# STM32WL54CCU6@M0 register map
File version: 1.0
Registers are 32-bit, access not given, reset 0x0 unless marked. A register's access mark holds for its fields unless they carry their own. Offsets are from the block's base; [hi:lo] are bit positions; {n}, {i} and the like mark numbered series.

## TAMP
Base 0x4000B000
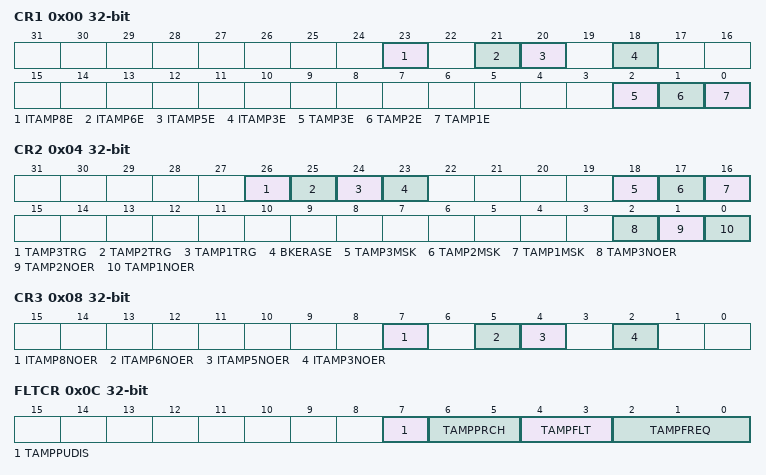
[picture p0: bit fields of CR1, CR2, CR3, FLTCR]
0x00 CR1
  [23] ITAMP8E, [21] ITAMP6E, [20] ITAMP5E, [18] ITAMP3E, [2] TAMP3E, [1] TAMP2E, [0] TAMP1E
0x04 CR2
  [26] TAMP3TRG, [25] TAMP2TRG, [24] TAMP1TRG, [23] BKERASE, [18] TAMP3MSK, [17] TAMP2MSK, [16] TAMP1MSK, [2] TAMP3NOER, [1] TAMP2NOER, [0] TAMP1NOER
0x08 CR3
  [7] ITAMP8NOER, [5] ITAMP6NOER, [4] ITAMP5NOER, [2] ITAMP3NOER
0x0C FLTCR
  [7] TAMPPUDIS, [6:5] TAMPPRCH, [4:3] TAMPFLT, [2:0] TAMPFREQ
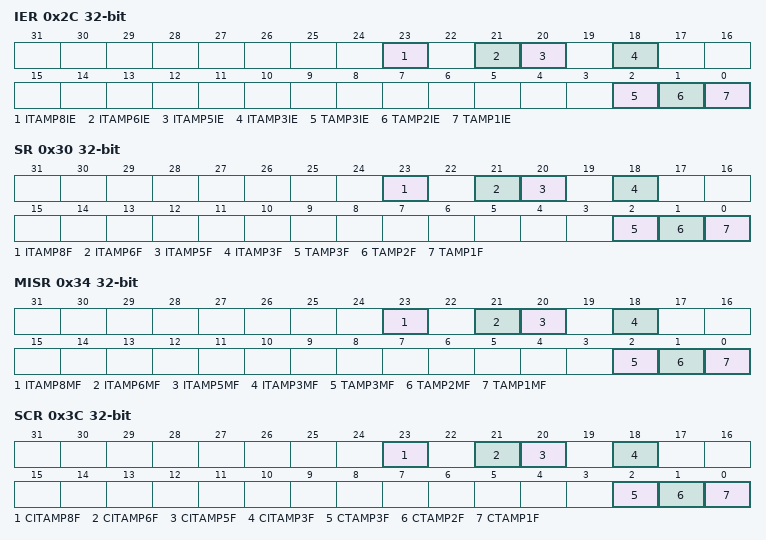
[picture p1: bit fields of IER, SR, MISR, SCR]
0x2C IER
  [23] ITAMP8IE, [21] ITAMP6IE, [20] ITAMP5IE, [18] ITAMP3IE, [2] TAMP3IE, [1] TAMP2IE, [0] TAMP1IE
0x30 SR
  [23] ITAMP8F, [21] ITAMP6F, [20] ITAMP5F, [18] ITAMP3F, [2] TAMP3F, [1] TAMP2F, [0] TAMP1F
0x34 MISR
  [23] ITAMP8MF, [21] ITAMP6MF, [20] ITAMP5MF, [18] ITAMP3MF, [2] TAMP3MF, [1] TAMP2MF, [0] TAMP1MF
0x3C SCR
  [23] CITAMP8F, [21] CITAMP6F, [20] CITAMP5F, [18] CITAMP3F, [2] CTAMP3F, [1] CTAMP2F, [0] CTAMP1F
0x40 COUNTR
  [31:0] COUNT
{0x100+4i} BKP{i}R (i=0..19)
  [31:0] BKP

## SYSCFG
Base 0x40010000
Same registers: SYSCFG 0x40010100, SYSCFG 0x40010100
0x00 MEMRMP
  [2:0] MEM_MODE
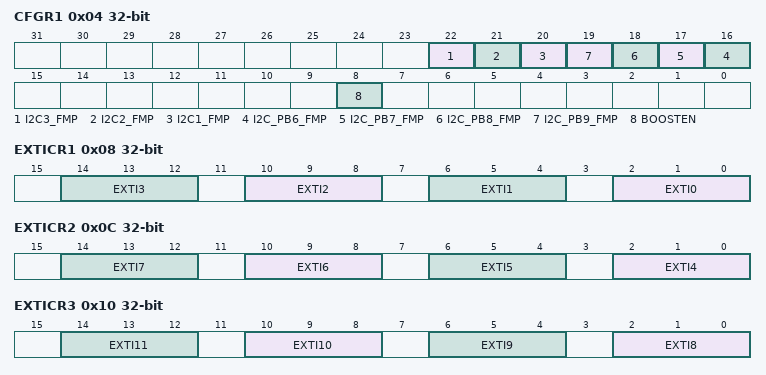
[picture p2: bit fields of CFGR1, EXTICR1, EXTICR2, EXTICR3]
0x04 CFGR1
  [22] I2C3_FMP, [21] I2C2_FMP, [20] I2C1_FMP, [n+10] I2C_PB{n}_FMP (n=6..9), [8] BOOSTEN
0x08 EXTICR1
  [4n+2:4n] EXTI{n} (n=0..3)
0x0C EXTICR2
  [4n-14:4n-16] EXTI{n} (n=4..7)
0x10 EXTICR3
  [4n-30:4n-32] EXTI{n} (n=8..11)
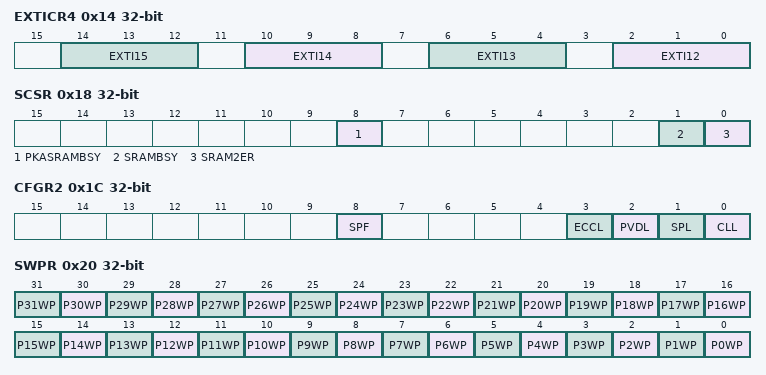
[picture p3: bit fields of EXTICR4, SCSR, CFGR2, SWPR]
0x14 EXTICR4
  [4n-46:4n-48] EXTI{n} (n=12..15)
0x18 SCSR
  [8] PKASRAMBSY, [1] SRAMBSY, [0] SRAM2ER
0x1C CFGR2
  [8] SPF, [3] ECCL, [2] PVDL, [1] SPL, [0] CLL
0x20 SWPR
  [n] P{n}WP (n=0..31)
0x24 SKR
  [7:0] KEY
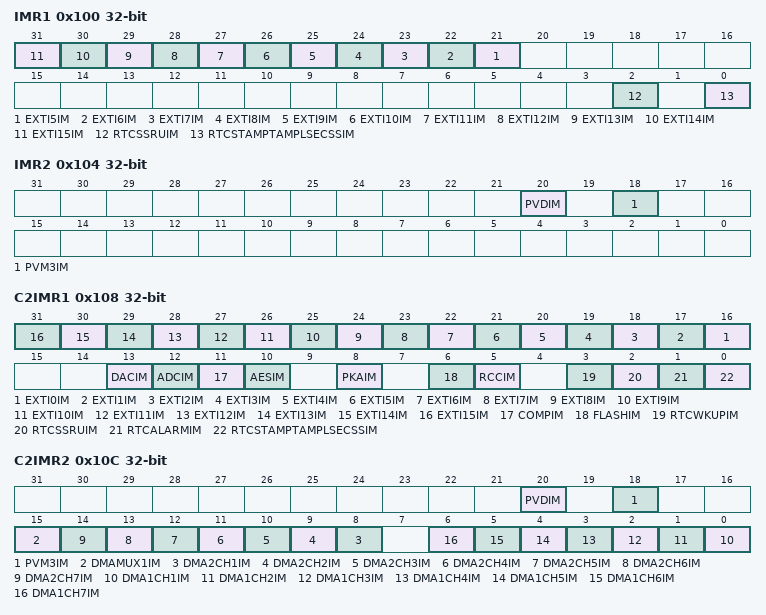
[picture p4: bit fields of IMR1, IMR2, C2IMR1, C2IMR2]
0x100 IMR1
  [n+16] EXTI{n}IM (n=5..15), [2] RTCSSRUIM, [0] RTCSTAMPTAMPLSECSSIM
0x104 IMR2
  [20] PVDIM, [18] PVM3IM
0x108 C2IMR1
  [n+16] EXTI{n}IM (n=0..15), [13] DACIM, [12] ADCIM, [11] COMPIM, [10] AESIM, [8] PKAIM, [6] FLASHIM, [5] RCCIM, [3] RTCWKUPIM, [2] RTCSSRUIM, [1] RTCALARMIM, [0] RTCSTAMPTAMPLSECSSIM
0x10C C2IMR2
  [20] PVDIM, [18] PVM3IM, [15] DMAMUX1IM, [n+7] DMA2CH{n}IM (n=1..7), [n-1] DMA1CH{n}IM (n=1..7)
0x208 RFDCR
  [0] RFTBSEL

## VREFBUF
Base 0x40010030
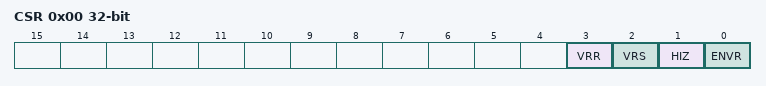
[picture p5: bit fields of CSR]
0x00 CSR
  [3] VRR, [2] VRS, [1] HIZ, [0] ENVR
0x04 CCR
  [5:0] TRIM

## COMP
Base 0x40010200
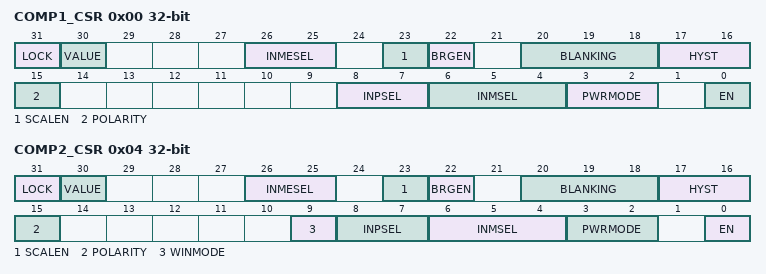
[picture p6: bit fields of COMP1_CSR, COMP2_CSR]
0x00 COMP1_CSR
  [31] LOCK, [30] VALUE, [26:25] INMESEL, [23] SCALEN, [22] BRGEN, [20:18] BLANKING, [17:16] HYST, [15] POLARITY, [8:7] INPSEL, [6:4] INMSEL, [3:2] PWRMODE, [0] EN
0x04 COMP2_CSR
  [31] LOCK, [30] VALUE, [26:25] INMESEL, [23] SCALEN, [22] BRGEN, [20:18] BLANKING, [17:16] HYST, [15] POLARITY, [9] WINMODE, [8:7] INPSEL, [6:4] INMSEL, [3:2] PWRMODE, [0] EN

## ADC
Base 0x40012400
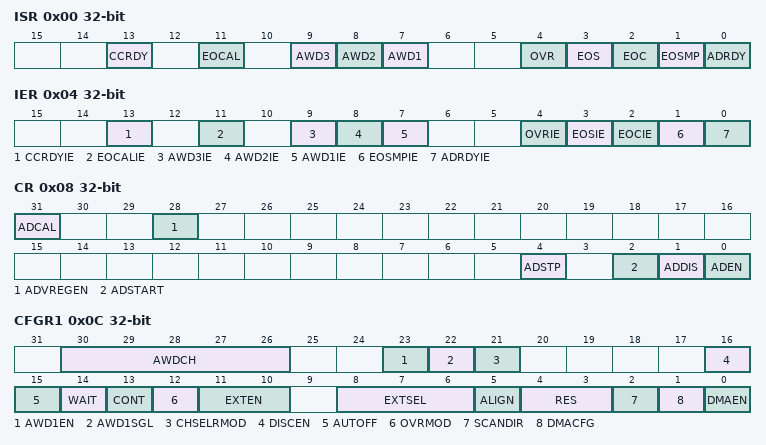
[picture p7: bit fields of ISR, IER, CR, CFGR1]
0x00 ISR
  [13] CCRDY, [11] EOCAL, [9] AWD3, [8] AWD2, [7] AWD1, [4] OVR, [3] EOS, [2] EOC, [1] EOSMP, [0] ADRDY
0x04 IER
  [13] CCRDYIE, [11] EOCALIE, [9] AWD3IE, [8] AWD2IE, [7] AWD1IE, [4] OVRIE, [3] EOSIE, [2] EOCIE, [1] EOSMPIE, [0] ADRDYIE
0x08 CR
  [31] ADCAL, [28] ADVREGEN, [4] ADSTP, [2] ADSTART, [1] ADDIS, [0] ADEN
0x0C CFGR1
  [30:26] AWDCH, [23] AWD1EN, [22] AWD1SGL, [21] CHSELRMOD, [16] DISCEN, [15] AUTOFF, [14] WAIT, [13] CONT, [12] OVRMOD, [11:10] EXTEN, [8:6] EXTSEL, [5] ALIGN, [4:3] RES, [2] SCANDIR, [1] DMACFG, [0] DMAEN
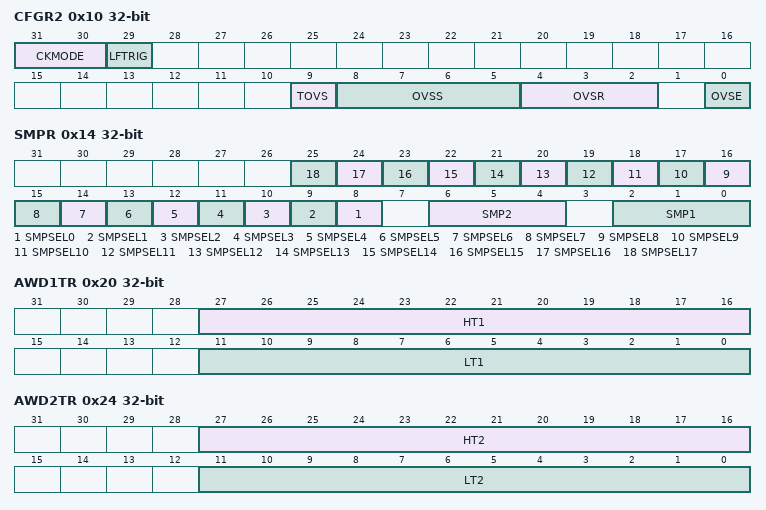
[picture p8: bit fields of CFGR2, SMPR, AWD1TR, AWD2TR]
0x10 CFGR2
  [31:30] CKMODE, [29] LFTRIG, [9] TOVS, [8:5] OVSS, [4:2] OVSR, [0] OVSE
0x14 SMPR
  [n+8] SMPSEL{n} (n=0..17), [6:4] SMP2, [2:0] SMP1
0x20 AWD1TR
  [27:16] HT1, [11:0] LT1
0x24 AWD2TR
  [27:16] HT2, [11:0] LT2
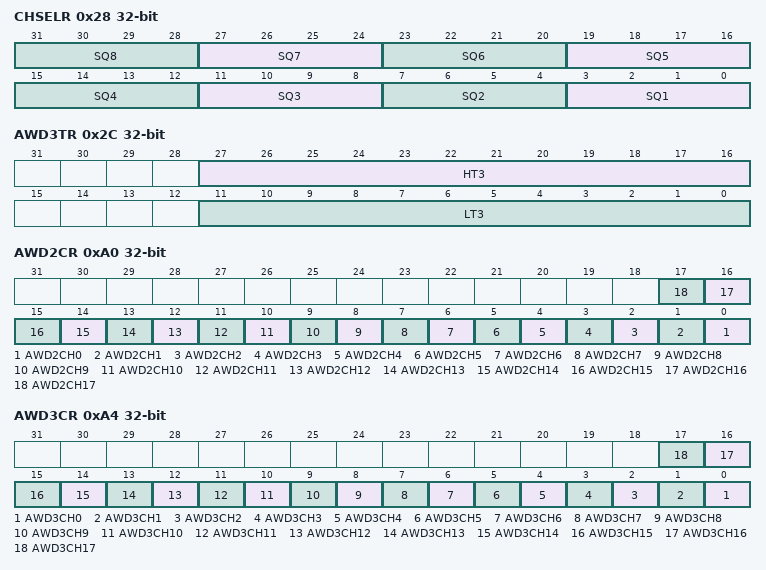
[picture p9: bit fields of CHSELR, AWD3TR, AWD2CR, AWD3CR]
0x28 CHSELR
  [4n-1:4n-4] SQ{n} (n=1..8)
0x2C AWD3TR
  [27:16] HT3, [11:0] LT3
0x40 DR
  [15:0] DATA
0xA0 AWD2CR
  [n] AWD2CH{n} (n=0..17)
0xA4 AWD3CR
  [n] AWD3CH{n} (n=0..17)
0xB4 CALFACT
  [6:0] CALFACT
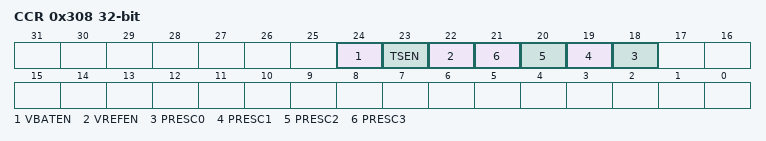
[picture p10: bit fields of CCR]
0x308 CCR
  [24] VBATEN, [23] TSEN, [22] VREFEN, [n+18] PRESC{n} (n=0..3)

## TIM1
Base 0x40012C00
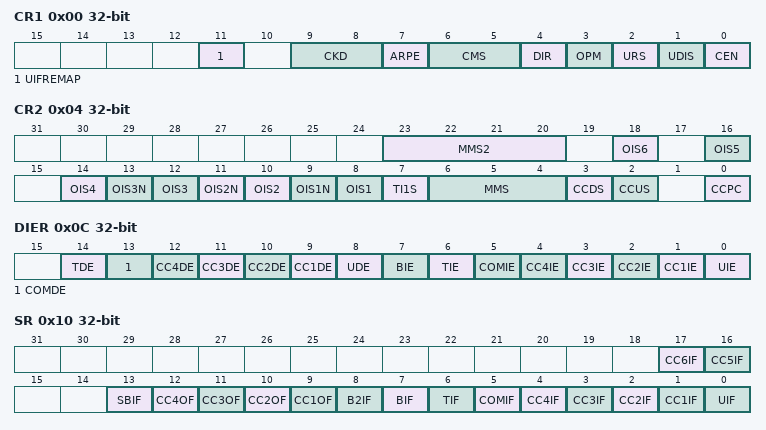
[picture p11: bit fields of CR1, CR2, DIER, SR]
0x00 CR1
  [11] UIFREMAP, [9:8] CKD, [7] ARPE, [6:5] CMS, [4] DIR, [3] OPM, [2] URS, [1] UDIS, [0] CEN
0x04 CR2
  [23:20] MMS2, [2n+6] OIS{n} (n=1..6), [13] OIS3N, [11] OIS2N, [9] OIS1N, [7] TI1S, [6:4] MMS, [3] CCDS, [2] CCUS, [0] CCPC
0x08 SMCR
  [15] ETP, [14] ECE, [13:12] ETPS, [11:8] ETF, [7] MSM, [21:4] TS, [3] OCCS, [16:0] SMS
0x0C DIER
  [14] TDE, [13] COMDE, [n+8] CC{n}DE (n=1..4), [8] UDE, [7] BIE, [6] TIE, [5] COMIE, [n] CC{n}IE (n=1..4), [0] UIE
0x10 SR
  [17] CC6IF, [16] CC5IF, [13] SBIF, [n+8] CC{n}OF (n=1..4), [8] B2IF, [7] BIF, [6] TIF, [5] COMIF, [n] CC{n}IF (n=1..4), [0] UIF
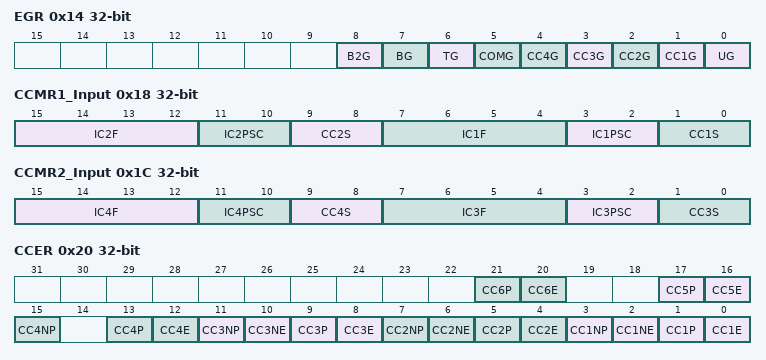
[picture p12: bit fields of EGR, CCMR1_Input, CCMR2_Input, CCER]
0x14 EGR
  [8] B2G, [7] BG, [6] TG, [5] COMG, [n] CC{n}G (n=1..4), [0] UG
0x18 CCMR1_Output
  [15] OC2CE, [24:12] OC2M, [11] OC2PE, [10] OC2FE, [9:8] CC2S, [7] OC1CE, [16:4] OC1M, [3] OC1PE, [2] OC1FE, [1:0] CC1S
0x18 CCMR1_Input
  [15:12] IC2F, [11:10] IC2PSC, [9:8] CC2S, [7:4] IC1F, [3:2] IC1PSC, [1:0] CC1S
0x1C CCMR2_Output
  [15] OC4CE, [24:12] OC4M, [11] OC4PE, [10] OC4FE, [9:8] CC4S, [7] OC3CE, [16:4] OC3M, [3] OC3PE, [2] OC3FE, [1:0] CC3S
0x1C CCMR2_Input
  [15:12] IC4F, [11:10] IC4PSC, [9:8] CC4S, [7:4] IC3F, [3:2] IC3PSC, [1:0] CC3S
0x20 CCER
  [4n-3] CC{n}P (n=1..6), [4n-4] CC{n}E (n=1..6), [4n-1] CC{n}NP (n=1..4), [10] CC3NE, [6] CC2NE, [2] CC1NE
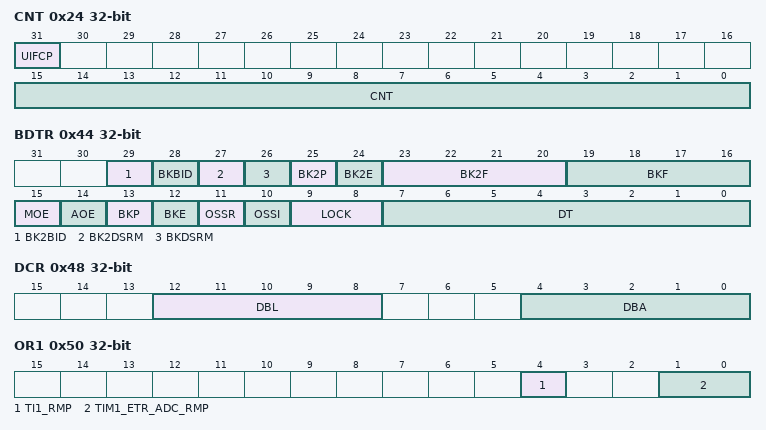
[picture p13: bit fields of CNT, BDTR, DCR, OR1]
0x24 CNT
  [31] UIFCP, [15:0] CNT
0x28 PSC
  [15:0] PSC
0x2C ARR
  [15:0] ARR
0x30 RCR
  [15:0] REP
{0x30+4i} CCR{i} (i=1..4)
  [15:0] CCR{i}
0x44 BDTR
  [29] BK2BID, [28] BKBID, [27] BK2DSRM, [26] BKDSRM, [25] BK2P, [24] BK2E, [23:20] BK2F, [19:16] BKF, [15] MOE, [14] AOE, [13] BKP, [12] BKE, [11] OSSR, [10] OSSI, [9:8] LOCK, [7:0] DT
0x48 DCR
  [12:8] DBL, [4:0] DBA
0x4C DMAR
  [31:0] DMAB
0x50 OR1
  [4] TI1_RMP, [1:0] TIM1_ETR_ADC_RMP
0x54 CCMR3_Output
  [15] OC6CE, [24:12] OC6M, [11] OC6PE, [10] OC6FE, [7] OC5CE, [16:4] OC5M, [3] OC5PE, [2] OC5FE
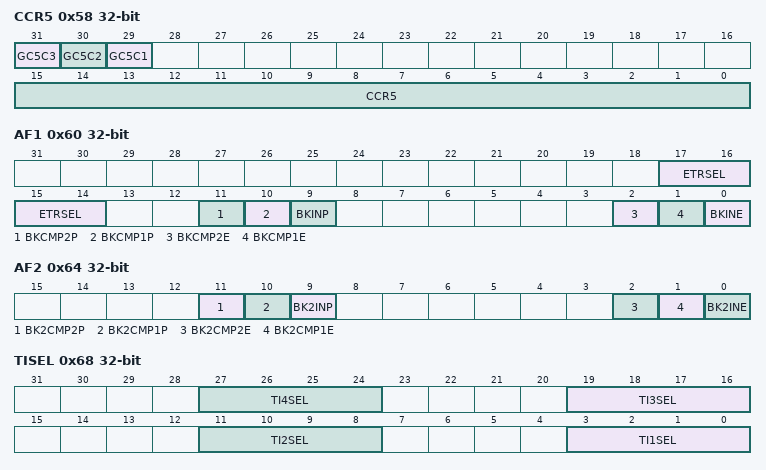
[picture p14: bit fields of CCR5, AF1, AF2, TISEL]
0x58 CCR5
  [31] GC5C3, [30] GC5C2, [29] GC5C1, [15:0] CCR5
0x5C CCR6
  [15:0] CCR6
0x60 AF1
  [17:14] ETRSEL, [11] BKCMP2P, [10] BKCMP1P, [9] BKINP, [2] BKCMP2E, [1] BKCMP1E, [0] BKINE
0x64 AF2
  [11] BK2CMP2P, [10] BK2CMP1P, [9] BK2INP, [2] BK2CMP2E, [1] BK2CMP1E, [0] BK2INE
0x68 TISEL
  [8n-5:8n-8] TI{n}SEL (n=1..4)
